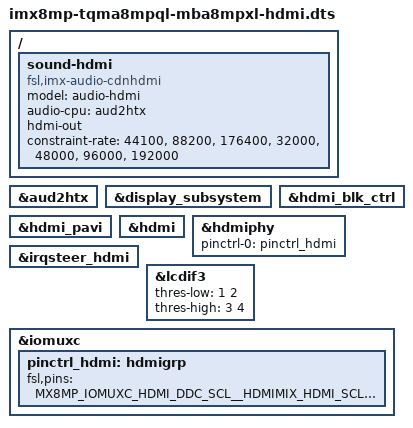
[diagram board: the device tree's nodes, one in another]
// SPDX-License-Identifier: (GPL-2.0-or-later OR MIT)
/*
 * Copyright 2021-2023 TQ-Systems GmbH <linux@ew.tq-group.com>,
 * D-82229 Seefeld, Germany.
 * Author: Alexander Stein
 */

#include "imx8mp-tqma8mpql-mba8mpxl.dts"

/ {
	sound-hdmi {
		compatible = "fsl,imx-audio-cdnhdmi";
		model = "audio-hdmi";
		audio-cpu = <&aud2htx>;
		hdmi-out;
		constraint-rate = <44100>,
				  <88200>,
				  <176400>,
				  <32000>,
				  <48000>,
				  <96000>,
				  <192000>;
		status = "okay";
	};
};

&aud2htx {
	status = "okay";
};

&display_subsystem {
	status = "okay";
};

&hdmi_blk_ctrl {
	status = "okay";
};

&hdmi_pavi {
	status = "okay";
};

&hdmi {
	status = "okay";
};

&hdmiphy {
	pinctrl-names = "default";
	pinctrl-0 = <&pinctrl_hdmi>;

	status = "okay";
};

&irqsteer_hdmi {
	status = "okay";
};

&lcdif3 {
	status = "okay";

	thres-low  = <1 2>;             /* (FIFO * 1 / 2) */
	thres-high = <3 4>;             /* (FIFO * 3 / 4) */
};

&iomuxc {
	pinctrl_hdmi: hdmigrp {
		fsl,pins = <
			MX8MP_IOMUXC_HDMI_DDC_SCL__HDMIMIX_HDMI_SCL	0x400001c3
			MX8MP_IOMUXC_HDMI_DDC_SDA__HDMIMIX_HDMI_SDA	0x400001c3
			MX8MP_IOMUXC_HDMI_HPD__HDMIMIX_HDMI_HPD		0x40000019
			MX8MP_IOMUXC_HDMI_CEC__HDMIMIX_HDMI_CEC		0x40000019
		>;
	};
};
